# S1C31W74 register map
Vendor: Epson; Series: S1C31W74; File version: 1.11
CPU: CM0PLUS r0p1, little endian, MPU, no FPU, VTOR, 2 interrupt priority bits
Registers are 16-bit, read-write, reset 0x0 unless marked. A register's access mark holds for its fields unless they carry their own. Offsets are from the block's base; [hi:lo] are bit positions.

## DMAC — PrimeCell uDMA Controller
Base 0x40001000
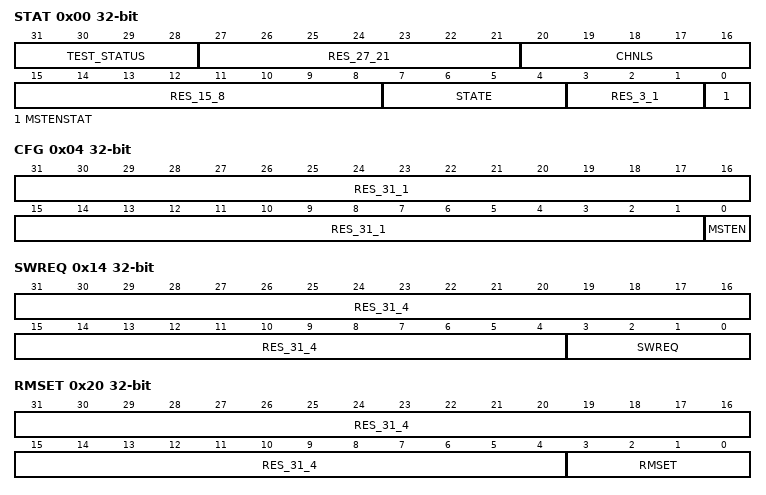
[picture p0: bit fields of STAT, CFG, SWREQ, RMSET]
0x00 STAT 32-bit ro — Returns the DMAC status
  [31:28] TEST_STATUS — TEST bits
  [27:21] RES_27_21 — Reserved bits
  [20:16] CHNLS — Number of available DMAC channels minus one
  [15:8] RES_15_8 — Reserved bits
  [7:4] STATE — These bits indicates the DMA transfer status
  [3:1] RES_3_1 — Reserved bits
  [0] MSTENSTAT — This bit indicates the DMA controller status
0x04 CFG 32-bit — DMA configuration
  [31:1] RES_31_1 ro — Reserved bits. Write as zero
  [0] MSTEN wo — This bit enables the DMA controller.
0x08 CPTR 32-bit — Pointer to the base address of the primary data structure
0x0C ACPTR 32-bit ro — Pointer to the base address of the alternative data structure
0x14 SWREQ 32-bit wo — The write-only register enables you to generate a software DMA request
  [31:4] RES_31_4 ro — Reserved bits
  [3:0] SWREQ — The write-only register enables you to generate a software DMA request
0x20 RMSET 32-bit — Setting this bit to 1 causes the DMA channel to no longer respond to data requests from peripherals. The channel will always respond to software transfer requests
  [31:4] RES_31_4 ro — Reserved bits
  [3:0] RMSET — Setting this bit to 1 causes the DMA channel to no longer respond to data requests from peripherals. The channel will always respond to software transfer requests
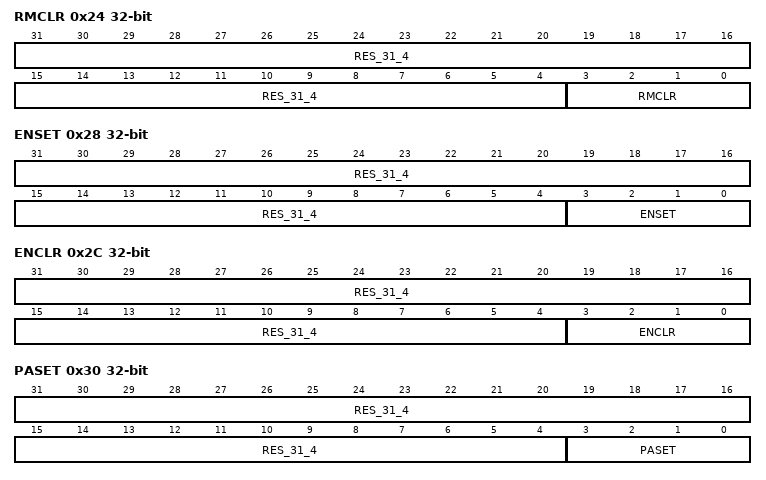
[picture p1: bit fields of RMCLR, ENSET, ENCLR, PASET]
0x24 RMCLR 32-bit wo — Firmware can write a 1 to the register to clear the mask for a channel
  [31:4] RES_31_4 ro — Reserved bits
  [3:0] RMCLR — Firmware can write a 1 to the register to clear the mask for a channel
0x28 ENSET 32-bit — These bits enable each DMAC channel. Returns the enable status of the channels
  [31:4] RES_31_4 ro — Reserved bits
  [3:0] ENSET — These bits enable each DMAC channel. Returns the enable status of the channels
0x2C ENCLR 32-bit wo — Set the appropriate bit to disable the corresponding DMA channel
  [31:4] RES_31_4 ro — Reserved bits
  [3:0] ENCLR — Set the appropriate bit to disable the corresponding DMA channel
0x30 PASET 32-bit — These bits enable the alternate data structures. Returns status of alternate structures.
  [31:4] RES_31_4 ro — Reserved bits
  [3:0] PASET — These bits enable the alternate data structures. Returns status of alternate structures.
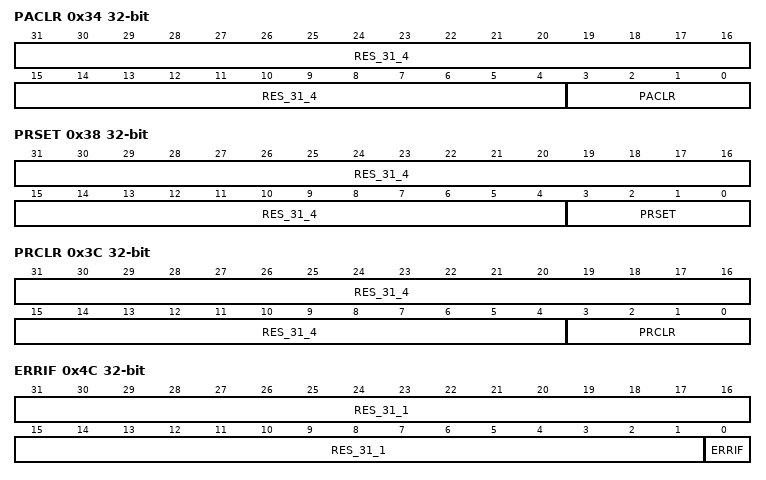
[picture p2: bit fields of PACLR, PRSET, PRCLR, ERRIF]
0x34 PACLR 32-bit wo — These bits disable the alternate data structures
  [31:4] RES_31_4 ro — Reserved bits
  [3:0] PACLR — These bits disable the alternate data structures
0x38 PRSET 32-bit — These bits increase the priority of each channel
  [31:4] RES_31_4 ro — Reserved bits
  [3:0] PRSET — These bits increase the priority of each channel
0x3C PRCLR 32-bit wo — These bits decrease the priority of each channel
  [31:4] RES_31_4 ro — Reserved bits
  [3:0] PRCLR — These bits decrease the priority of each channel
0x4C ERRIF 32-bit — DMAC Error Interrupt Flag Register
  [31:1] RES_31_1 ro — Reserved bits. Read as zero
  [0] ERRIF — Returns the status of DMAC error. Cleared by writing 1
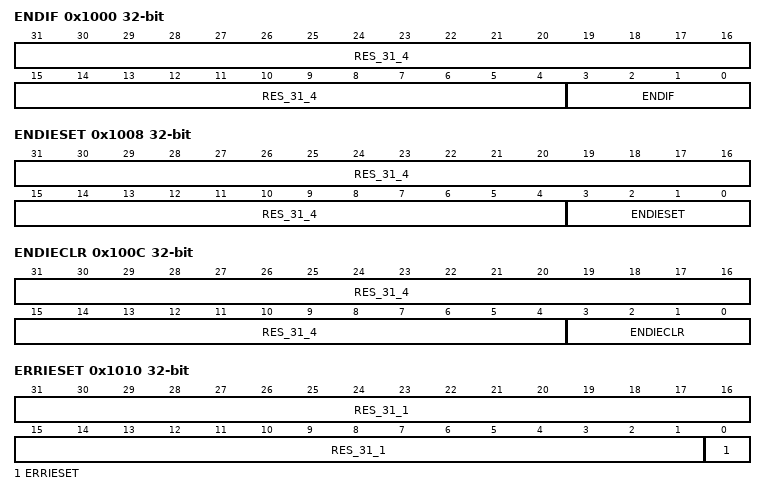
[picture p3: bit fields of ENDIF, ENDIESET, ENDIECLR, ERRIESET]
0x1000 ENDIF 32-bit — DMAC Transfer Completion Interrupt Flag Register
  [31:4] RES_31_4 ro — Reserved bits
  [3:0] ENDIF — DMAC transfer completion interrupt flag
0x1008 ENDIESET 32-bit — DMAC Transfer Completion Interrupt Enable Set Register
  [31:4] RES_31_4 ro — Reserved bits
  [3:0] ENDIESET — Set DMAC transfer completion interrupt enable
0x100C ENDIECLR 32-bit wo — DMAC Transfer Completion Interrupt Enable Clear Register
  [31:4] RES_31_4 ro — Reserved bits
  [3:0] ENDIECLR — Clear DMAC transfer completion interrupt enable
0x1010 ERRIESET 32-bit — DMAC Error Interrupt Enable Set Register
  [31:1] RES_31_1 ro — Reserved bits. Read as zero
  [0] ERRIESET — This bit enables DMA error interrupts
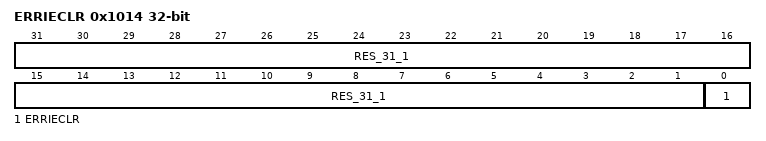
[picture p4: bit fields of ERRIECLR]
0x1014 ERRIECLR 32-bit wo — DMAC Error Interrupt Enable Clear Register
  [31:1] RES_31_1 ro — Reserved bits. Read as zero
  [0] ERRIECLR — This bit disables DMA error interrupts
